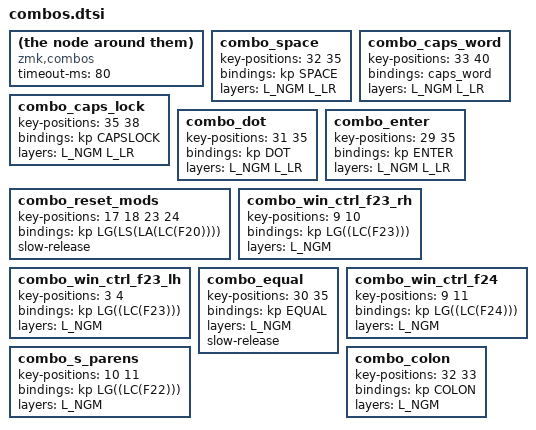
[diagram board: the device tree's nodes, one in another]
/* aka "Chords" */
/* NOTES
    https://zmk.dev/docs/features/combos
    https://zmk.dev/docs/config/combos

    timeout-ms: must hit combo w/in that time
    layers = <0 1 ...> // OPTIONAL - to restrict combo to only work on that/those layers
    some (this file) refs work due to #include order in upper/other files
 */

compatible = "zmk,combos";
timeout-ms = <80>;

// [A] SPACE
combo_space {
    key-positions = <32 35>; // L-index, L-thumb
    bindings = <&kp SPACE>;
    layers = <L_NGM L_LR>;
};

// [B] CAPS-WORD
combo_caps_word {
key-positions = <33 40>; // {RH-index-in-1; LH-index-in-1}
bindings = <&caps_word>;
layers = <L_NGM L_LR>;
};

// [C] CAPS-LOCK
combo_caps_lock {
    key-positions = <35 38>; // Both top/inner smaller thumb keys (currently each assigned to Shift)
    bindings = <&kp CAPSLOCK>;
    layers = <L_NGM L_LR>;
};

// [D] PERIOD
combo_dot {
    key-positions = <31 35>; // L-middle, L-thumb
    bindings = <&kp DOT>;
    layers = <L_NGM L_LR>;
};

// [E] ENTER
combo_enter {
    key-positions = <29 35>; // L-pinkie, L-thumb
    bindings = <&kp ENTER>;
    layers = <L_NGM L_LR>;
};

// [F] RESET MODs when stuck / ▣ 2025-02-09 / WIP / NOT WORKING WELL
combo_reset_mods {
    key-positions = <17 18 23 24>; // RH+LH 2 inner fingers 1 row up
    bindings = <&kp LG(LS(LA(LC(F20))))>; // SEE AHK
    //layers = <L_NGM>; - ALL
    slow-release; // optional - seems will only fire combo after ALL are released / 2025-03-27 TBD - will help prevent stuck mods?
};

// [G] "..." - Win+Ctrl+F23 / AHK: "..." (separate, Ø … char)
combo_win_ctrl_f23_rh {
    key-positions = <9 10>; // top row (.
    bindings = <&kp LG((LC(F23)))>; // SEE AHK
    layers = <L_NGM>;
};
combo_win_ctrl_f23_lh {
    key-positions = <3 4>; // top row ,'
    bindings = <&kp LG((LC(F23)))>; // SEE AHK
    layers = <L_NGM>;
};

// [H] =
combo_equal {
    key-positions = <30 35>; // L-index+1, L-thumb
    bindings = <&kp EQUAL>;
    layers = <L_NGM>;
    slow-release; // optional - seems will only fire combo after ALL are released
};

// [I] - Win+Ctrl+F24 / AHK: "(){Left}"
combo_win_ctrl_f24 {
    key-positions = <9 11>; // top row ()
    bindings = <&kp LG((LC(F24)))>; // SEE AHK
    layers = <L_NGM>;
};

// [J] "(s)"
combo_s_parens {
    key-positions = <10 11>; // top row .)
    bindings = <&kp LG((LC(F22)))>; // SEE AHK
    layers = <L_NGM>;
};

// [K] COLON (:)
combo_colon {
    key-positions = <32 33>; // LH: {a;}
    bindings = <&kp COLON>;
    layers = <L_NGM>;
};

